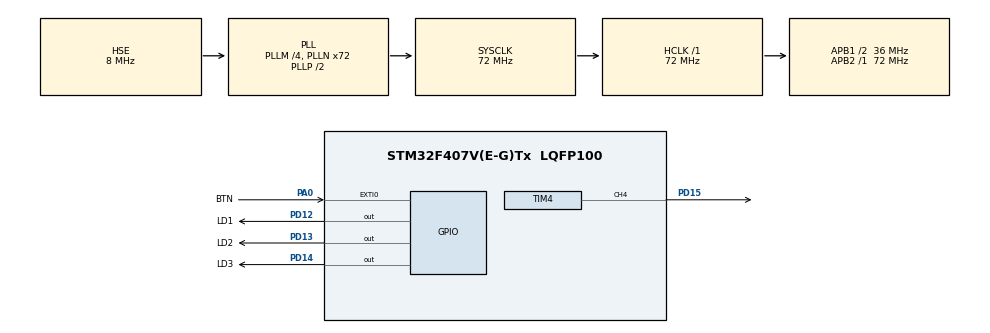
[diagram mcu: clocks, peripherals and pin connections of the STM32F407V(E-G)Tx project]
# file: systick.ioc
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Mcu.Family=STM32F4
Mcu.Name=STM32F407V(E-G)Tx
Mcu.Package=LQFP100
NVIC.EXTI0_IRQn=true\:1\:0\:true\:false\:true\:true\:true
NVIC.PriorityGroup=NVIC_PRIORITYGROUP_4
NVIC.TIM4_IRQn=true\:0\:0\:false\:false\:true\:true\:true
NVIC.TIM6_DAC_IRQn=true\:0\:0\:false\:false\:true\:true\:true
PA0-WKUP.GPIO_Label=BTN
PA0-WKUP.Signal=GPXTI0
PD12.GPIO_Label=LD1
PD12.Signal=GPIO_Output
PD13.GPIO_Label=LD2
PD13.Signal=GPIO_Output
PD14.GPIO_Label=LD3
PD14.Signal=GPIO_Output
PD15.Signal=S_TIM4_CH4
PH0-OSC_IN.Mode=HSE-External-Oscillator
PH0-OSC_IN.Signal=RCC_OSC_IN
PH1-OSC_OUT.Mode=HSE-External-Oscillator
PH1-OSC_OUT.Signal=RCC_OSC_OUT
ProjectManager.HeapSize=0x200
ProjectManager.StackSize=0x400
ProjectManager.TargetToolchain=STM32CubeIDE
RCC.48MHZClocksFreq_Value=36000000
RCC.AHBFreq_Value=72000000
RCC.APB1CLKDivider=RCC_HCLK_DIV2
RCC.APB1Freq_Value=36000000
RCC.APB1TimFreq_Value=72000000
RCC.APB2Freq_Value=72000000
RCC.APB2TimFreq_Value=72000000
RCC.CortexFreq_Value=72000000
RCC.HCLKFreq_Value=72000000
RCC.HSE_VALUE=8000000
RCC.HSI_VALUE=16000000
RCC.LSE_VALUE=32768
RCC.PLLM=4
RCC.PLLN=72
RCC.PLLSourceVirtual=RCC_PLLSOURCE_HSE
RCC.SYSCLKFreq_VALUE=72000000
RCC.SYSCLKSource=RCC_SYSCLKSOURCE_PLLCLK
RCC.VCOOutputFreq_Value=144000000
SH.S_TIM4_CH4.0=TIM4_CH4,PWM Generation4 CH4
TIM4.AutoReloadPreload=TIM_AUTORELOAD_PRELOAD_ENABLE
TIM4.Channel-PWM\ Generation4\ CH4=TIM_CHANNEL_4
TIM4.Period=200
TIM4.Prescaler=36000
TIM4.Pulse-PWM\ Generation4\ CH4=50
TIM6.AutoReloadPreload=TIM_AUTORELOAD_PRELOAD_ENABLE
TIM6.Period=499
TIM6.Prescaler=3599
VP_TIM4_VS_ClockSourceINT.Mode=Internal
VP_TIM6_VS_ClockSourceINT.Mode=Enable_Timer
board=custom

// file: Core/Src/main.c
/* USER CODE BEGIN Header */
/**
  ******************************************************************************
  * @file           : main.c
  * @brief          : Main program body
  ******************************************************************************
  * @attention
  *
  * <h2><center>&copy; Copyright (c) 2021 STMicroelectronics.
  * All rights reserved.</center></h2>
  *
  * This software component is licensed by ST under BSD 3-Clause license,
  * the "License"; You may not use this file except in compliance with the
  * License. You may obtain a copy of the License at:
  *                        opensource.org/licenses/BSD-3-Clause
  *
  ******************************************************************************
  */
/* USER CODE END Header */
#include "main.h"
#include "tim.h"
#include "gpio.h"

/* USER CODE BEGIN Includes */
#include "debounce.h"

/* USER CODE END Includes */

/* USER CODE BEGIN PV */
tmr_callback_fnc_t  tim6_cb_ptr;
void  timer_callback_register(void* user_fn);

/* USER CODE END PV */

void SystemClock_Config(void);

/* USER CODE BEGIN 0 */
extern int sw_rtc_app_run (void);
/* USER CODE END 0 */

int main(void)
{

  /* MCU Configuration--------------------------------------------------------*/

  /* Reset of all peripherals, Initializes the Flash interface and the Systick. */
  HAL_Init();

  /* Configure the system clock */
  SystemClock_Config();

  /* Initialize all configured peripherals */
  MX_GPIO_Init();
  MX_TIM4_Init();
  MX_TIM6_Init();
  /* USER CODE BEGIN 2 */
//  timer_callback_register(sw_rtc_systick_update);
  sw_rtc_app_run();
  /* USER CODE END 2 */

  /* Infinite loop */
  while (1)
  {

    /* USER CODE BEGIN 3 */
	 /* debouce_run_test(); */
  }
  /* USER CODE END 3 */
}

void SystemClock_Config(void)
{
  RCC_OscInitTypeDef RCC_OscInitStruct = {0};
  RCC_ClkInitTypeDef RCC_ClkInitStruct = {0};

  /** Configure the main internal regulator output voltage
  */
  __HAL_RCC_PWR_CLK_ENABLE();
  __HAL_PWR_VOLTAGESCALING_CONFIG(PWR_REGULATOR_VOLTAGE_SCALE1);
  /** Initializes the RCC Oscillators according to the specified parameters
  * in the RCC_OscInitTypeDef structure.
  */
  RCC_OscInitStruct.OscillatorType = RCC_OSCILLATORTYPE_HSE;
  RCC_OscInitStruct.HSEState = RCC_HSE_ON;
  RCC_OscInitStruct.PLL.PLLState = RCC_PLL_ON;
  RCC_OscInitStruct.PLL.PLLSource = RCC_PLLSOURCE_HSE;
  RCC_OscInitStruct.PLL.PLLM = 4;
  RCC_OscInitStruct.PLL.PLLN = 72;
  RCC_OscInitStruct.PLL.PLLP = RCC_PLLP_DIV2;
  RCC_OscInitStruct.PLL.PLLQ = 4;
  if (HAL_RCC_OscConfig(&RCC_OscInitStruct) != HAL_OK)
  {
    Error_Handler();
  }
  /** Initializes the CPU, AHB and APB buses clocks
  */
  RCC_ClkInitStruct.ClockType = RCC_CLOCKTYPE_HCLK|RCC_CLOCKTYPE_SYSCLK
                              |RCC_CLOCKTYPE_PCLK1|RCC_CLOCKTYPE_PCLK2;
  RCC_ClkInitStruct.SYSCLKSource = RCC_SYSCLKSOURCE_PLLCLK;
  RCC_ClkInitStruct.AHBCLKDivider = RCC_SYSCLK_DIV1;
  RCC_ClkInitStruct.APB1CLKDivider = RCC_HCLK_DIV2;
  RCC_ClkInitStruct.APB2CLKDivider = RCC_HCLK_DIV1;

  if (HAL_RCC_ClockConfig(&RCC_ClkInitStruct, FLASH_LATENCY_2) != HAL_OK)
  {
    Error_Handler();
  }
}

/* USER CODE BEGIN 4 */
void  timer_callback_register(void* user_fn)
{
	tim6_cb_ptr = (tmr_callback_fnc_t)user_fn;
}
/* USER CODE END 4 */

void Error_Handler(void)
{
  __disable_irq();
  while (1)
  {
  }
}

/************************ (C) COPYRIGHT STMicroelectronics *****END OF FILE****/
